# RE01_256KB register map
Vendor: Renesas Electronics Corporation; Series: RE01; File version: 1.00.01
CPU: CM0PLUS r0p1, little endian, MPU, no FPU, VTOR, 2 interrupt priority bits, 32 interrupts
Registers are 8-bit, read-write, reset 0x0 unless marked. A register's access mark holds for its fields unless they carry their own. Offsets are from the block's base; [hi:lo] are bit positions; 'fields as' and 'values as' point back to an identical list.

## FACI — Flash Application Command Interface
Base 0x407FE000
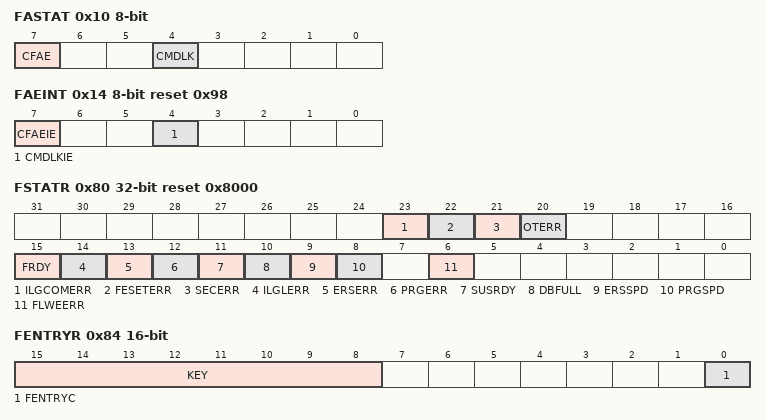
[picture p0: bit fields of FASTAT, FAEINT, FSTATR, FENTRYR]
0x10 FASTAT — Flash Access Status Register
  [7] CFAE — Code Flash Memory Access Violation Flag
    0=No code flash memory access violation has occurred; 1=A code flash memory access violation has occurred
  [4] CMDLK ro — Command Lock Flag
    0=The flash sequencer is not in the command-locked state; 1=The flash sequencer is in the command-locked state
0x14 FAEINT reset 0x98 — Flash Access Error Interrupt Enable Register
  [7] CFAEIE — Code Flash Memory Access Violation Interrupt Enable
    0=Generation of an FCU_FIFERR interrupt request is disabled when FASTAT.CFAE is set to 1; 1=Generation of an FCU_FIFERR interrupt request is enabled when FASTAT.CFAE is set to 1
  [4] CMDLKIE — Command Lock Interrupt Enable
    0=Generation of an FCU_FIFERR interrupt request is disabled when FASTAT.CMDLK is set to 1; 1=Generation of an FCU_FIFERR interrupt request is enabled when FASTAT.CMDLK is set to 1
0x18 FRDYIE — Flash Ready Interrupt Enable Register
  [0] FRDYIE — Flash Ready Interrupt Enable
    0=FCU_FRDYI interrupt request does not occur when the FSTATR.FRDY flag is changed from 0 to 1; 1=FCU_FRDYI interrupt request occurs when the FSTATR.FRDY flag is changed from 0 to 1
0x30 FSADDR 32-bit — FACI Command Start Address Register
  [31:0] FSADDR — Start Address for FACI Command Processing
0x80 FSTATR 32-bit reset 0x8000 — Flash Status Register
  [23] ILGCOMERR ro — Illegal Command Error
    0=A status clear or forced stop command processing is complete; 1=An error has occurred
  [22] FESETERR ro — FENTRY Setting Error
    values as ILGCOMERR
  [21] SECERR ro — Security Error
    values as ILGCOMERR
  [20] OTERR ro — Other Error
    values as ILGCOMERR
  [15] FRDY ro — Flash Ready Flag
    0=Program, block erase, P/E suspend, P/E resume, forced stop, or configuration set command processing is in progress; 1=None of the above is in progress
  [14] ILGLERR ro — Illegal Command Error Flag
    0=The flash sequencer has not detected an illegal FACI command or illegal flash memory access; 1=The flash sequencer has detected an illegal FACI command or illegal flash memory access
  [13] ERSERR ro — Erasure Error Flag
    0=Erasure has completed successfully; 1=An error has occurred during erasure
  [12] PRGERR ro — Programming Error Flag
    0=Programming has completed successfully; 1=An error has occurred during programming
  [11] SUSRDY ro — Suspend Ready Flag
    0=The flash sequencer cannot receive P/E suspend commands; 1=The flash sequencer can receive P/E suspend commands
  [10] DBFULL ro — Data Buffer Full Flag
    0=The data buffer is empty; 1=The data buffer is full
  [9] ERSSPD ro — Erasure Suspend Status Flag
    0=The flash sequencer is in a state other than those corresponding to the value 1; 1=The flash sequencer is in the erasure suspension processing state or the erasure suspended state
  [8] PRGSPD ro — Programming Suspend Status Flag
    0=The flash sequencer is in a state other than those corresponding to the value 1; 1=The flash sequencer is in the programming suspension processing state or programming suspended state
  [6] FLWEERR ro — Flash Write/Erase Protect Error Flag
    0=An error has not occurred; 1=An error has occurred
0x84 FENTRYR 16-bit — Flash P/E Mode Entry Register
  [15:8] KEY — Key Code
  [0] FENTRYC — Code Flash P/E Mode Entry
    0=Code flash is in read mode; 1=Code flash is in P/E mode
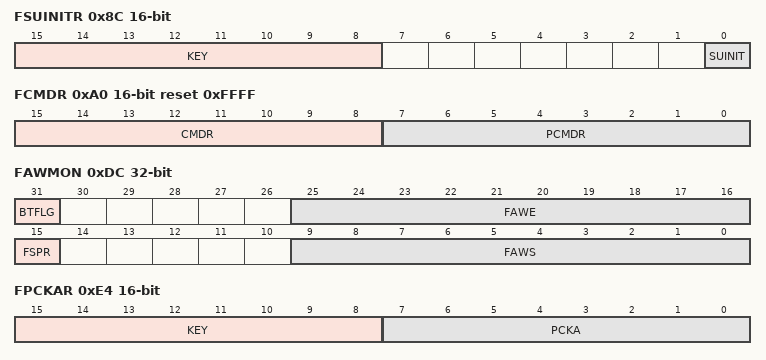
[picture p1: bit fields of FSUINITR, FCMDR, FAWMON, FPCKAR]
0x8C FSUINITR 16-bit — Flash Sequencer Setup Initialization Register
  [15:8] KEY — Key Code
  [0] SUINIT — Set-Up Initialization
    0=The above flash sequencer set-up registers keep their current values; 1=The above flash sequencer set-up registers are initialized
0xA0 FCMDR 16-bit ro reset 0xFFFF — FACI Command Register
  [15:8] CMDR — Command Flag
  [7:0] PCMDR — Pre-command Flag
0xDC FAWMON 32-bit ro (reset mask 0x7C007C00) — Flash Access Window Monitor Register
  [31] BTFLG — Startup Area Select Flag
    0=Block 8 to block 15 are used as a startup area; 1=Block 0 to Block 7 are used as a startup area (initial value)
  [25:16] FAWE — Flash Access Window End Address
  [15] FSPR — Access Window Protection Flag
    0=Protection available (execution is impossible); 1=Protection unavailable (execution is possible)
  [9:0] FAWS — Flash Access Window Start Address
0xE4 FPCKAR 16-bit (reset mask 0xFF00) — Flash Sequencer Processing Clock Notification Register
  [15:8] KEY — Key Code
  [7:0] PCKA — Flash Sequencer Operating Clock Notification
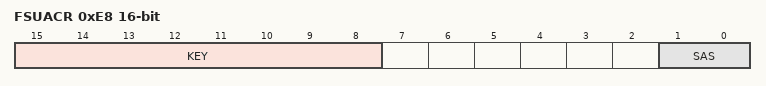
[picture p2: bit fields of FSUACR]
0xE8 FSUACR 16-bit (reset mask 0xFFFC) — Flash Startup Area Control Register
  [15:8] KEY — Key Code
  [1:0] SAS — Startup Area Select
    0b0x=A startup area is selected in accordance with the setting of the BTFLG flag of the AWS register in section x, Option-Setting Memory; 2=The startup area of blocks 0 to 7 is used regardless of the setting of the BTFLG flag of the AWS register in section x, Option-Setting Memory. In the case of a reset after the setting of the above value, a startup area conforms to the setting of the BTFLG flag.; 3=The startup area of blocks 8 to 15 is used regardless of the setting of the BTFLG flag of the AWS register in section x, Option-Setting Memory. In the case of a reset after the setting of the above value, a startup area conforms to the setting of the BTFLG flag.
